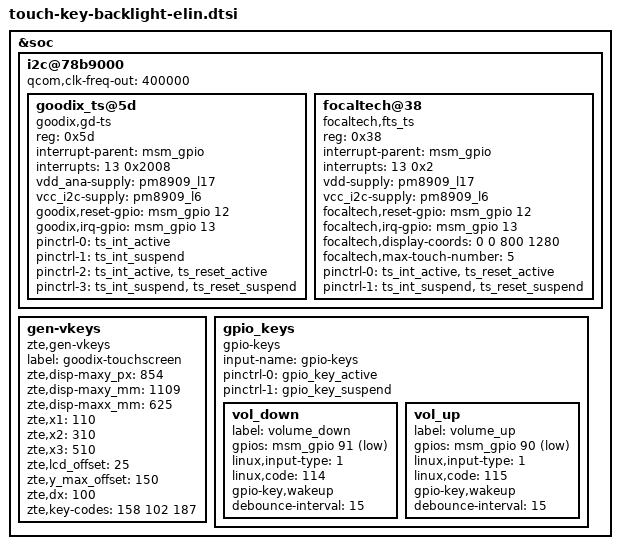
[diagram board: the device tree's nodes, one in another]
&soc {
	i2c@78b9000 { /* BLSP1 QUP5 */
		qcom,clk-freq-out = <400000>;
		goodix_ts@5d {
			compatible = "goodix,gd-ts";
			reg = <0x5d>;
			interrupt-parent = <&msm_gpio>;
			interrupts = <13 0x2008>;
			vdd_ana-supply = <&pm8909_l17>;
			vcc_i2c-supply = <&pm8909_l6>;
			goodix,reset-gpio = <&msm_gpio 12 0x00>;
			goodix,irq-gpio = <&msm_gpio 13 0x00>;
			pinctrl-names = "pmx_ts_active","pmx_ts_suspend",
							"pmx_ts_init","pmx_ts_release";
			pinctrl-0 = <&ts_int_active>;
			pinctrl-1 = <&ts_int_suspend>;
			pinctrl-2 = <&ts_int_active &ts_reset_active>;
			pinctrl-3 = <&ts_int_suspend &ts_reset_suspend>;
		};

		focaltech@38{
			compatible = "focaltech,fts_ts";
			reg = <0x38>;
			interrupt-parent = <&msm_gpio>;
			interrupts = <13 0x2>;
			vdd-supply = <&pm8909_l17>;
			vcc_i2c-supply = <&pm8909_l6>;
			focaltech,reset-gpio = <&msm_gpio 12 0x00>;
			focaltech,irq-gpio = <&msm_gpio 13 0x00>;
			focaltech,display-coords = <0 0 800 1280>;
			focaltech,max-touch-number = <5>;
			pinctrl-names = "pmx_ts_active","pmx_ts_suspend";
			pinctrl-0 = <&ts_int_active &ts_reset_active>;
			pinctrl-1 = <&ts_int_suspend &ts_reset_suspend>;
		};
	};

	gen-vkeys {
		compatible = "zte,gen-vkeys";
		label = "goodix-touchscreen";
		zte,disp-maxy_px = <854>;
		zte,disp-maxy_mm = <1109>;
		zte,disp-maxx_mm = <625>;
		zte,x1=<110>;
		zte,x2=<310>;
		zte,x3=<510>;
		zte,lcd_offset=<25>;
		zte,y_max_offset=<150>;
		zte,dx=<100>;
		zte,key-codes = <158 102 187>;
	};

	gpio_keys {
		compatible = "gpio-keys";
		input-name = "gpio-keys";
		pinctrl-names = "tlmm_gpio_key_active","tlmm_gpio_key_suspend";
		pinctrl-0 = <&gpio_key_active>;
		pinctrl-1 = <&gpio_key_suspend>;

		vol_down {
			label = "volume_down";
			gpios = <&msm_gpio 91 0x1>;
			linux,input-type = <1>;
			linux,code = <114>;
			gpio-key,wakeup;
			debounce-interval = <15>;
		};
		vol_up {
			label = "volume_up";
			gpios = <&msm_gpio 90 0x1>;
			linux,input-type = <1>;
			linux,code = <115>;
			gpio-key,wakeup;
			debounce-interval = <15>;
		};
	};

};
